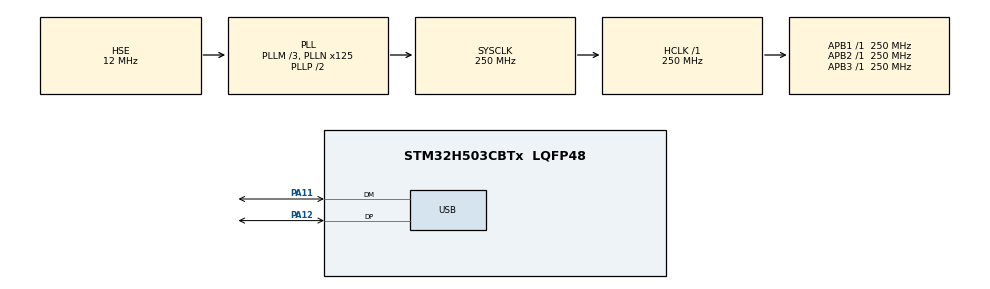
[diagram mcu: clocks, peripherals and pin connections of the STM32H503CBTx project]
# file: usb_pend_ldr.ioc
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BOOTPATH.BootPathName=LEGACY
BOOTPATH.UserSelectedBootPath=LEGACY
Mcu.Family=STM32H5
Mcu.Name=STM32H503CBTx
Mcu.Package=LQFP48
NVIC.PriorityGroup=NVIC_PRIORITYGROUP_4
NVIC.USB_DRD_FS_IRQn=true\:0\:0\:false\:false\:true\:true\:true\:true
PA11.Mode=Device
PA11.Signal=USB_DM
PA12.Mode=Device
PA12.Signal=USB_DP
PH0-OSC_IN(PH0).Mode=HSE-External-Oscillator
PH0-OSC_IN(PH0).Signal=RCC_OSC_IN
PH1-OSC_OUT(PH1).Mode=HSE-External-Oscillator
PH1-OSC_OUT(PH1).Signal=RCC_OSC_OUT
ProjectManager.HeapSize=0x300
ProjectManager.StackSize=0x500
ProjectManager.TargetToolchain=Makefile
RCC.ADCCLockSelection=RCC_ADCDACCLKSOURCE_CSI
RCC.ADCFreq_Value=4000000
RCC.AHBFreq_Value=250000000
RCC.APB1Freq_Value=250000000
RCC.APB1TimFreq_Value=250000000
RCC.APB2Freq_Value=250000000
RCC.APB2TimFreq_Value=250000000
RCC.APB3Freq_Value=250000000
RCC.CSI_VALUE=4000000
RCC.CortexFreq_Value=250000000
RCC.EPOD_VALUE=12000000
RCC.EnbaleCSS=true
RCC.HCLKFreq_Value=250000000
RCC.HSE_VALUE=12000000
RCC.HSI48_VALUE=48000000
RCC.HSI_VALUE=64000000
RCC.LSE_VALUE=32768
RCC.LSIRC_VALUE=32000
RCC.PLL2FRACN=0
RCC.PLL2Source=RCC_PLL2_SOURCE_HSE
RCC.PLLFRACN=0
RCC.PLLM=3
RCC.PLLN=125
RCC.PLLSourceVirtual=RCC_PLL1_SOURCE_HSE
RCC.SYSCLKFreq_VALUE=250000000
RCC.SYSCLKSource=RCC_SYSCLKSOURCE_PLLCLK
RCC.USBFreq_Value=48000000
RCC.VCOOutputFreq_Value=500000000
USB.VirtualMode=Device_Only
VP_BOOTPATH_VS_BOOTPATH.Mode=BP_Activate
VP_CORTEX_M33_NS_VS_Hclk.Mode=Hclk_Mode
VP_FLASH_SIG_Activate_FlashIP.Mode=Activate_FlashIP
VP_ICACHE_VS_ICACHE.Mode=DirectMappedCache
VP_MEMORYMAP_VS_MEMORYMAP.Mode=CurAppReg
VP_PWR_VS_DBSignals.Mode=DisableDeadBatterySignals
VP_PWR_VS_LPOM.Mode=PowerOptimisation
VP_PWR_VS_SECSignals.Mode=Security/Privilege
board=custom

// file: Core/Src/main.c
/* USER CODE BEGIN Header */
/**
  ******************************************************************************
  * @file           : main.c
  * @brief          : Main program body
  ******************************************************************************
  * @attention
  *
  * Copyright (c) 2025 STMicroelectronics.
  * All rights reserved.
  *
  * This software is licensed under terms that can be found in the LICENSE file
  * in the root directory of this software component.
  * If no LICENSE file comes with this software, it is provided AS-IS.
  *
  ******************************************************************************
  */
/* USER CODE END Header */
#include "main.h"

/* USER CODE BEGIN Includes */
#include "usbd_core.h"
#include "usbd_device.h"
#include "platform.h"
/* USER CODE END Includes */

/* USER CODE BEGIN PTD */
USBD_HandleTypeDef hUsbDeviceFS = {0};
extern USBD_DescriptorsTypeDef usbd_class_descriptors;
/* USER CODE END PTD */

PCD_HandleTypeDef hpcd_USB_DRD_FS;

void SystemClock_Config(void);
static void MX_GPIO_Init(void);
static void MX_FLASH_Init(void);
static void MX_ICACHE_Init(void);
static void MX_USB_PCD_Init(void);

int main(void)
{

  /* MCU Configuration--------------------------------------------------------*/

  /* Reset of all peripherals, Initializes the Flash interface and the Systick. */
  HAL_Init();

  /* Configure the system clock */
  SystemClock_Config();

  /* Initialize all configured peripherals */
  MX_GPIO_Init();
  MX_FLASH_Init();
  MX_ICACHE_Init();
  MX_USB_PCD_Init();
  /* USER CODE BEGIN 2 */
  init();
  /* USER CODE END 2 */

  /* Infinite loop */
  /* USER CODE BEGIN WHILE */
  while (1)
  {
    loop();
    /* USER CODE END WHILE */

  }
}

void SystemClock_Config(void)
{
  RCC_OscInitTypeDef RCC_OscInitStruct = {0};
  RCC_ClkInitTypeDef RCC_ClkInitStruct = {0};

  /** Configure the main internal regulator output voltage
  */
  __HAL_PWR_VOLTAGESCALING_CONFIG(PWR_REGULATOR_VOLTAGE_SCALE0);

  while(!__HAL_PWR_GET_FLAG(PWR_FLAG_VOSRDY)) {}

  /** Initializes the RCC Oscillators according to the specified parameters
  * in the RCC_OscInitTypeDef structure.
  */
  RCC_OscInitStruct.OscillatorType = RCC_OSCILLATORTYPE_HSI48|RCC_OSCILLATORTYPE_HSE;
  RCC_OscInitStruct.HSEState = RCC_HSE_ON;
  RCC_OscInitStruct.HSI48State = RCC_HSI48_ON;
  RCC_OscInitStruct.PLL.PLLState = RCC_PLL_ON;
  RCC_OscInitStruct.PLL.PLLSource = RCC_PLL1_SOURCE_HSE;
  RCC_OscInitStruct.PLL.PLLM = 3;
  RCC_OscInitStruct.PLL.PLLN = 125;
  RCC_OscInitStruct.PLL.PLLP = 2;
  RCC_OscInitStruct.PLL.PLLQ = 2;
  RCC_OscInitStruct.PLL.PLLR = 2;
  RCC_OscInitStruct.PLL.PLLRGE = RCC_PLL1_VCIRANGE_2;
  RCC_OscInitStruct.PLL.PLLVCOSEL = RCC_PLL1_VCORANGE_WIDE;
  RCC_OscInitStruct.PLL.PLLFRACN = 0;
  if (HAL_RCC_OscConfig(&RCC_OscInitStruct) != HAL_OK)
  {
    Error_Handler();
  }

  /** Initializes the CPU, AHB and APB buses clocks
  */
  RCC_ClkInitStruct.ClockType = RCC_CLOCKTYPE_HCLK|RCC_CLOCKTYPE_SYSCLK
                              |RCC_CLOCKTYPE_PCLK1|RCC_CLOCKTYPE_PCLK2
                              |RCC_CLOCKTYPE_PCLK3;
  RCC_ClkInitStruct.SYSCLKSource = RCC_SYSCLKSOURCE_PLLCLK;
  RCC_ClkInitStruct.AHBCLKDivider = RCC_SYSCLK_DIV1;
  RCC_ClkInitStruct.APB1CLKDivider = RCC_HCLK_DIV1;
  RCC_ClkInitStruct.APB2CLKDivider = RCC_HCLK_DIV1;
  RCC_ClkInitStruct.APB3CLKDivider = RCC_HCLK_DIV1;

  if (HAL_RCC_ClockConfig(&RCC_ClkInitStruct, FLASH_LATENCY_5) != HAL_OK)
  {
    Error_Handler();
  }

  /** Enables the Clock Security System
  */
  HAL_RCC_EnableCSS();

  /** Configure the programming delay
  */
  __HAL_FLASH_SET_PROGRAM_DELAY(FLASH_PROGRAMMING_DELAY_2);
}

static void MX_FLASH_Init(void)
{

  if (HAL_FLASH_Unlock() != HAL_OK)
  {
    Error_Handler();
  }
  if (HAL_FLASH_Lock() != HAL_OK)
  {
    Error_Handler();
  }

}

static void MX_ICACHE_Init(void)
{

  /** Enable instruction cache in 1-way (direct mapped cache)
  */
  if (HAL_ICACHE_ConfigAssociativityMode(ICACHE_1WAY) != HAL_OK)
  {
    Error_Handler();
  }
  if (HAL_ICACHE_Enable() != HAL_OK)
  {
    Error_Handler();
  }

}

static void MX_USB_PCD_Init(void)
{

  /* USER CODE BEGIN USB_Init 0 */
  hpcd_USB_DRD_FS.pData = &hUsbDeviceFS;
  /* USER CODE END USB_Init 0 */

  hpcd_USB_DRD_FS.Instance = USB_DRD_FS;
  hpcd_USB_DRD_FS.Init.dev_endpoints = 8;
  hpcd_USB_DRD_FS.Init.speed = USBD_FS_SPEED;
  hpcd_USB_DRD_FS.Init.phy_itface = PCD_PHY_EMBEDDED;
  hpcd_USB_DRD_FS.Init.Sof_enable = DISABLE;
  hpcd_USB_DRD_FS.Init.low_power_enable = DISABLE;
  hpcd_USB_DRD_FS.Init.lpm_enable = DISABLE;
  hpcd_USB_DRD_FS.Init.battery_charging_enable = DISABLE;
  hpcd_USB_DRD_FS.Init.vbus_sensing_enable = DISABLE;
  hpcd_USB_DRD_FS.Init.bulk_doublebuffer_enable = DISABLE;
  hpcd_USB_DRD_FS.Init.iso_singlebuffer_enable = DISABLE;
  if (HAL_PCD_Init(&hpcd_USB_DRD_FS) != HAL_OK)
  {
    Error_Handler();
  }
  /* USER CODE BEGIN USB_Init 2 */
	if(USBD_Init(&hUsbDeviceFS, &usbd_class_descriptors, 0) != USBD_OK) Error_Handler();
	if(USBD_RegisterClass(&hUsbDeviceFS, &usbd_class_device) != USBD_OK) Error_Handler();
	if(USBD_Start(&hUsbDeviceFS) != USBD_OK) Error_Handler();
  /* USER CODE END USB_Init 2 */

}

static void MX_GPIO_Init(void)
{

  /* GPIO Ports Clock Enable */
  __HAL_RCC_GPIOH_CLK_ENABLE();
  __HAL_RCC_GPIOA_CLK_ENABLE();

}

void Error_Handler(void)
{
  __disable_irq();
  while (1)
  {
  }
}
